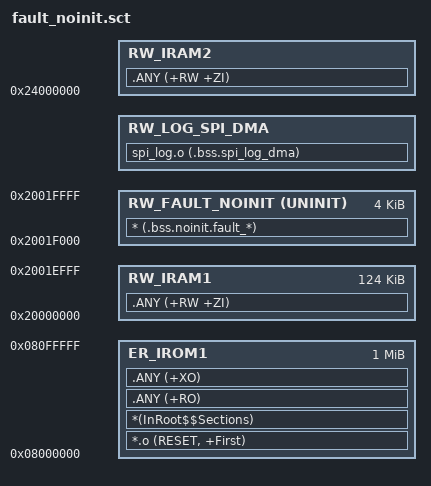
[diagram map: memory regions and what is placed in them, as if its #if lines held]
#! armclang -E --target=arm-arm-none-eabi -mcpu=cortex-m7 -xc
#include "fault_log_config.h"
#include "spi_log_config.h"
/* H723：保留故障现场，并为 SPI DMA 分配独立的 AXI SRAM。 */
LR_IROM1 0x08000000 0x00100000 {
  ER_IROM1 0x08000000 0x00100000 {
    *.o (RESET, +First)
    *(InRoot$$Sections)
    .ANY (+RO)
    .ANY (+XO)
  }
  RW_IRAM1 0x20000000 0x0001F000 {
    .ANY (+RW +ZI)
  }
#if FAULT_LOG_TEST_IRAM1
  RW_FAULT_NOINIT 0x2001F000 UNINIT 0x00001000 {
#else
  RW_FAULT_NOINIT 0x2404F000 UNINIT 0x00001000 {
#endif
    * (.bss.noinit.fault_*)
  }
  RW_LOG_SPI_DMA LOG_SPI_DMA_BASE LOG_SPI_DMA_BYTES {
    spi_log.o (.bss.spi_log_dma)
  }
  RW_IRAM2 0x24000000 (LOG_SPI_DMA_BASE - 0x24000000) {
    .ANY (+RW +ZI)
  }
}
